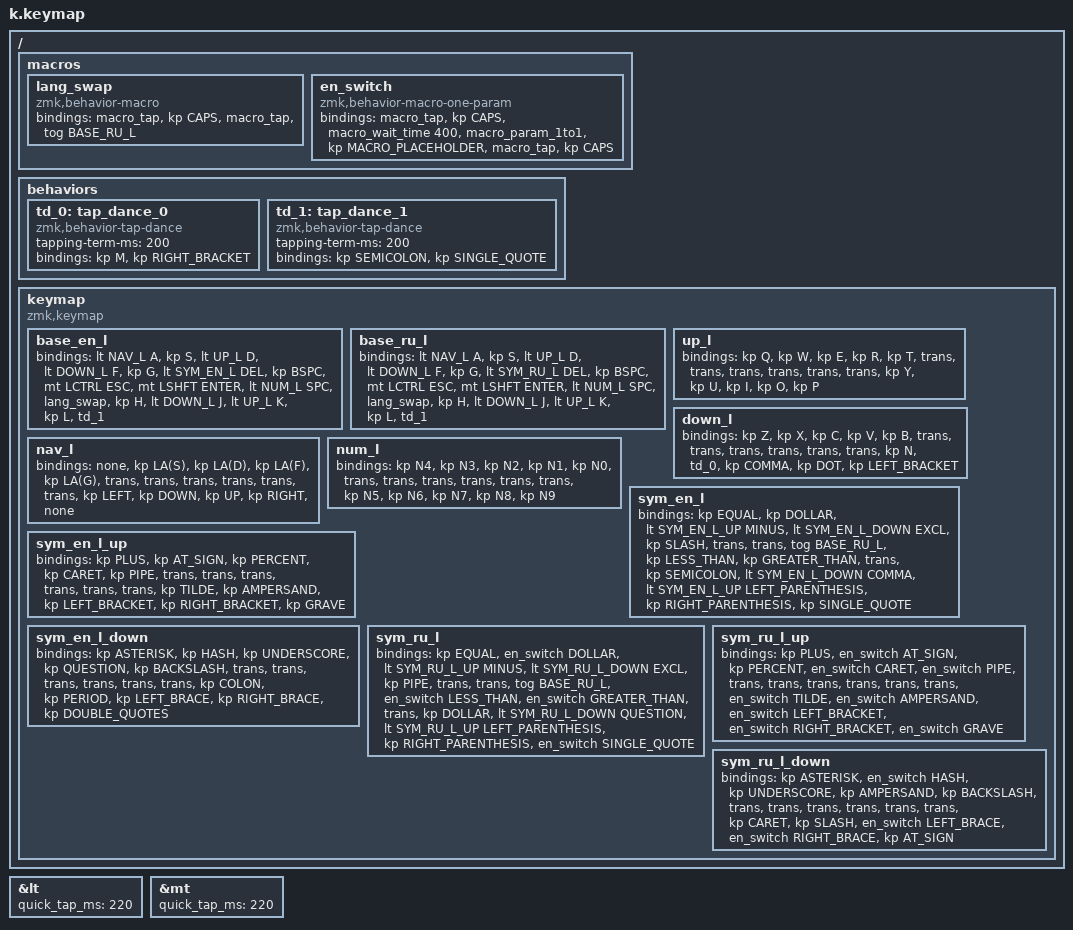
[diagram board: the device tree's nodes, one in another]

#include <behaviors.dtsi>
#include <dt-bindings/zmk/keys.h>

&lt { quick_tap_ms = <220>; };
&mt { quick_tap_ms = <220>; };

#define BASE_EN_L 0
#define BASE_RU_L 1
#define UP_L 2
#define DOWN_L 3
#define NAV_L 4
#define NUM_L 5
#define SYM_EN_L 6
#define SYM_EN_L_UP 7
#define SYM_EN_L_DOWN 8
#define SYM_RU_L 9
#define SYM_RU_L_UP 10
#define SYM_RU_L_DOWN 11

/ {
    macros {
        lang_swap: lang_swap {
            compatible = "zmk,behavior-macro";
            #binding-cells = <0>;
            bindings
                = <&macro_tap &kp CAPS>
                , <&macro_tap &tog BASE_RU_L>
                ;
        };
        en_switch: en_switch {
            compatible = "zmk,behavior-macro-one-param";
            #binding-cells = <1>;
            bindings
                = <&macro_tap &kp CAPS>
                , <&macro_wait_time 400>
                , <&macro_param_1to1 &kp MACRO_PLACEHOLDER>
                , <&macro_tap &kp CAPS>
                ;
        };
    };
    behaviors {
        // ъ
        td_0: tap_dance_0 {
            compatible = "zmk,behavior-tap-dance";
            #binding-cells = <0>;
            tapping-term-ms = <200>;
            bindings = <&kp M>, <&kp RIGHT_BRACKET>;
        };

        // э
        td_1: tap_dance_1 {
            compatible = "zmk,behavior-tap-dance";
            #binding-cells = <0>;
            tapping-term-ms = <200>;
            bindings = <&kp SEMICOLON>, <&kp SINGLE_QUOTE>;
        };
    };
    keymap {
        compatible = "zmk,keymap";

        base_en_l {
            bindings = <
                &lt NAV_L A   &kp S   &lt UP_L D   &lt DOWN_L F   &kp G   &lt SYM_EN_L DEL   &kp BSPC   &mt LCTRL ESC   &mt LSHFT ENTER   &lt NUM_L SPC   &lang_swap   &kp H   &lt DOWN_L J  &lt UP_L K   &kp L   &td_1
            >;
        };

        base_ru_l {
            bindings = <
                &lt NAV_L A   &kp S   &lt UP_L D   &lt DOWN_L F   &kp G   &lt SYM_RU_L DEL   &kp BSPC   &mt LCTRL ESC   &mt LSHFT ENTER   &lt NUM_L SPC   &lang_swap   &kp H   &lt DOWN_L J  &lt UP_L K   &kp L   &td_1
            >;
        };

        up_l {
            bindings = <
                &kp Q   &kp W   &kp E   &kp R   &kp T   &trans   &trans   &trans   &trans   &trans   &trans   &kp Y   &kp U   &kp I   &kp O   &kp P
            >;
        };

        down_l {
            bindings = <
                &kp Z   &kp X   &kp C   &kp V   &kp B   &trans   &trans   &trans   &trans   &trans   &trans   &kp N   &td_0   &kp COMMA   &kp DOT   &kp LEFT_BRACKET
            >;
        };

        nav_l {
            bindings = <
                &none   &kp LA(S)   &kp LA(D)   &kp LA(F)   &kp LA(G)   &trans   &trans   &trans   &trans   &trans   &trans   &kp LEFT   &kp DOWN   &kp UP   &kp RIGHT   &none
            >;
        };

        num_l {
            bindings = <
                &kp N4   &kp N3   &kp N2   &kp N1   &kp N0   &trans   &trans   &trans   &trans   &trans   &trans   &kp N5   &kp N6   &kp N7   &kp N8   &kp N9
            >;
        };

        sym_en_l {
            bindings = <
                &kp EQUAL   &kp DOLLAR   &lt SYM_EN_L_UP MINUS   &lt SYM_EN_L_DOWN EXCL   &kp SLASH   &trans   &trans   &tog BASE_RU_L   &kp LESS_THAN   &kp GREATER_THAN   &trans   &kp SEMICOLON   &lt SYM_EN_L_DOWN COMMA   &lt SYM_EN_L_UP LEFT_PARENTHESIS   &kp RIGHT_PARENTHESIS   &kp SINGLE_QUOTE
            >;
        };

        sym_en_l_up {
            bindings = <
                &kp PLUS  &kp AT_SIGN  &kp PERCENT  &kp CARET  &kp PIPE  &trans   &trans   &trans   &trans   &trans   &trans   &kp TILDE  &kp AMPERSAND  &kp LEFT_BRACKET  &kp RIGHT_BRACKET   &kp GRAVE
            >;
        };

        sym_en_l_down {
            bindings = <
                &kp ASTERISK   &kp HASH   &kp UNDERSCORE   &kp QUESTION   &kp BACKSLASH   &trans   &trans   &trans   &trans   &trans   &trans   &kp COLON   &kp PERIOD   &kp LEFT_BRACE  &kp RIGHT_BRACE   &kp DOUBLE_QUOTES
            >;
        };

        sym_ru_l {
            bindings = <
                &kp EQUAL   &en_switch DOLLAR   &lt SYM_RU_L_UP MINUS   &lt SYM_RU_L_DOWN EXCL   &kp PIPE   &trans   &trans   &tog BASE_RU_L   &en_switch LESS_THAN   &en_switch GREATER_THAN   &trans   &kp DOLLAR   &lt SYM_RU_L_DOWN QUESTION   &lt SYM_RU_L_UP LEFT_PARENTHESIS   &kp RIGHT_PARENTHESIS  &en_switch SINGLE_QUOTE
            >;
        };

        sym_ru_l_up {
            bindings = <
                &kp PLUS  &en_switch AT_SIGN  &kp PERCENT  &en_switch CARET  &en_switch PIPE  &trans   &trans   &trans   &trans   &trans   &trans   &en_switch TILDE  &en_switch AMPERSAND  &en_switch LEFT_BRACKET  &en_switch RIGHT_BRACKET   &en_switch GRAVE
            >;
        };

        sym_ru_l_down {
            bindings = <
                &kp ASTERISK   &en_switch HASH   &kp UNDERSCORE   &kp AMPERSAND   &kp BACKSLASH   &trans   &trans   &trans   &trans   &trans   &trans   &kp CARET   &kp SLASH   &en_switch LEFT_BRACE  &en_switch RIGHT_BRACE   &kp AT_SIGN
            >;
        };
    };
 };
